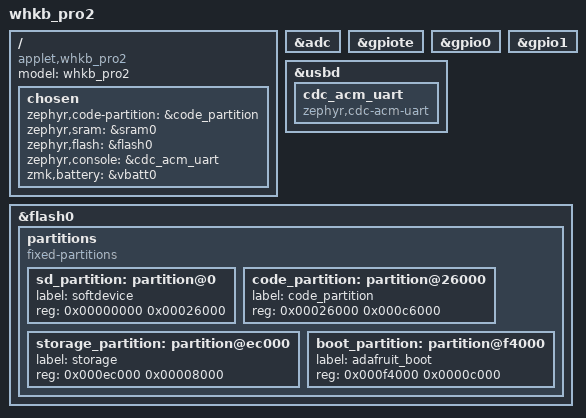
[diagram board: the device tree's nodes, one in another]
/*
 * Copyright (c) 2021 The ZMK Contributors
 *
 * SPDX-License-Identifier: MIT
 */

/dts-v1/;
#include <nordic/nrf52840_qiaa.dtsi>
#include <zephyr/dt-bindings/gpio/nordic-nrf-gpio.h>

/ {
    model = "whkb_pro2";
    compatible = "applet,whkb_pro2";

    chosen {
        zephyr,code-partition = &code_partition;
        zephyr,sram = &sram0;
        zephyr,flash = &flash0;
        zephyr,console = &cdc_acm_uart;
        zmk,battery = &vbatt0;
    };
};

&adc {
    status = "okay";
};

&gpiote {
    status = "okay";
};

&gpio0 {
    status = "okay";
};

&gpio1 {
    status = "okay";
};

zephyr_udc0: &usbd {
    status = "okay";
    cdc_acm_uart: cdc_acm_uart {
        compatible = "zephyr,cdc-acm-uart";
    };
};

&flash0 {
    /*
     * For more information, see:
     * http://docs.zephyrproject.org/latest/devices/dts/flash_partitions.html
     */
    partitions {
        compatible = "fixed-partitions";
        #address-cells = <1>;
        #size-cells = <1>;

        sd_partition: partition@0 {
            label = "softdevice";
            reg = <0x00000000 0x00026000>;
        };
        code_partition: partition@26000 {
            label = "code_partition";
            reg = <0x00026000 0x000c6000>;
        };

        /*
         * The flash starting at 0x000ec000 and ending at
         * 0x000f3fff is reserved for use by the application.
         */

        /*
         * Storage partition will be used by FCB/LittleFS/NVS
         * if enabled.
         */
        storage_partition: partition@ec000 {
            label = "storage";
            reg = <0x000ec000 0x00008000>;
        };

        boot_partition: partition@f4000 {
            label = "adafruit_boot";
            reg = <0x000f4000 0x0000c000>;
        };
    };
};
